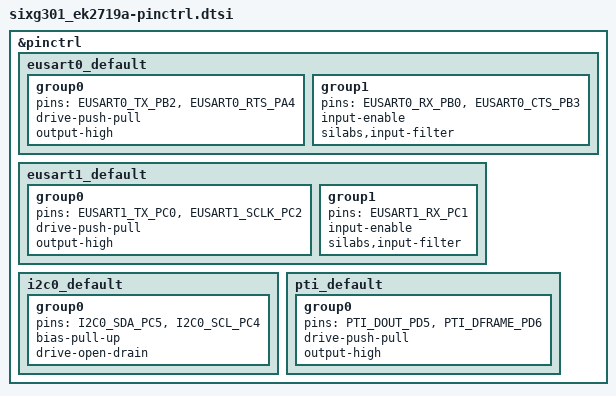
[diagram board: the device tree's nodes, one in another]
/*
 * Copyright The Zephyr Project Contributors
 *
 * SPDX-License-Identifier: Apache-2.0
 */
#include <zephyr/dt-bindings/pinctrl/silabs/six301-pinctrl.h>

&pinctrl {
	eusart0_default: eusart0_default {
		group0 {
			pins = <EUSART0_TX_PB2>, <EUSART0_RTS_PA4>;
			drive-push-pull;
			output-high;
		};

		group1 {
			pins = <EUSART0_RX_PB0>, <EUSART0_CTS_PB3>;
			input-enable;
			silabs,input-filter;
		};
	};

	eusart1_default: eusart1_default {
		group0 {
			pins = <EUSART1_TX_PC0>, <EUSART1_SCLK_PC2>;
			drive-push-pull;
			output-high;
		};

		group1 {
			pins = <EUSART1_RX_PC1>;
			input-enable;
			silabs,input-filter;
		};
	};

	i2c0_default: i2c0_default {
		group0 {
			pins = <I2C0_SDA_PC5>, <I2C0_SCL_PC4>;
			bias-pull-up;
			drive-open-drain;
		};
	};

	pti_default: pti_default {
		group0 {
			pins = <PTI_DOUT_PD5>, <PTI_DFRAME_PD6>;
			drive-push-pull;
			output-high;
		};
	};
};
